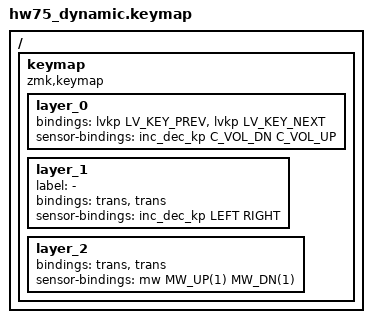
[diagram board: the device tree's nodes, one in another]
/*
 * Copyright (c) 2022 The ZMK Contributors
 * SPDX-License-Identifier: MIT
 */

#include <behaviors.dtsi>
#include <behaviors/lvgl_key_press.dtsi>
#include <behaviors/sensor_rotate_mouse_wheel.dtsi>
#include <dt-bindings/zmk/keys.h>
#include <dt-bindings/zmk/rgb.h>
#include <dt-bindings/zmk/lvgl.h>
#include <dt-bindings/zmk/mouse.h>

/ {
	keymap {
		compatible = "zmk,keymap";
		layer_0 {
			label = "音量";
			bindings = <&lvkp LV_KEY_PREV &lvkp LV_KEY_NEXT>;
			sensor-bindings = <&inc_dec_kp C_VOL_DN C_VOL_UP>;
		};

		layer_1 {
			label = "<->";
			bindings = <&trans &trans>;
			sensor-bindings = <&inc_dec_kp LEFT RIGHT>;
		};

		layer_2 {
			label = "滚动";
			bindings = <&trans &trans>;
			sensor-bindings = <&mw MW_UP(1) MW_DN(1)>;
		};
	};
};
